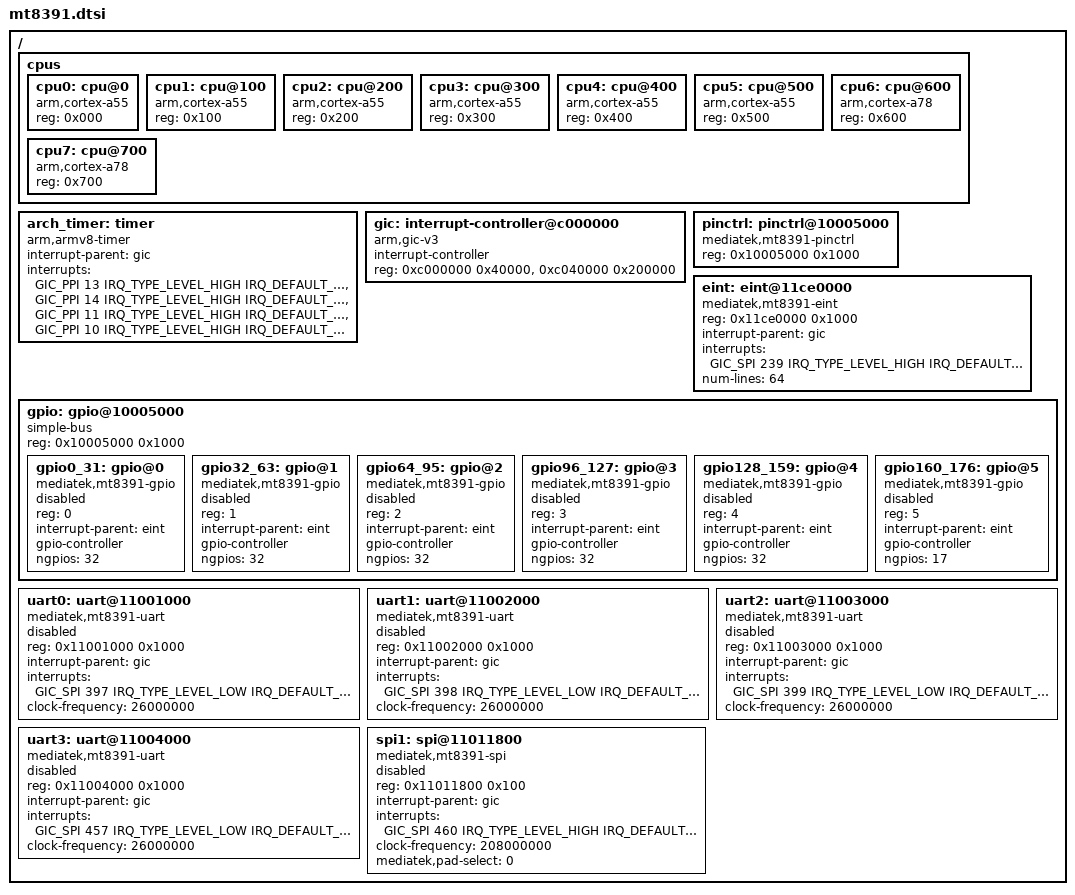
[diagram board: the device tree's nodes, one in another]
// SPDX-License-Identifier: GPL-2.0+
/*
 * Copyright (c) 2025 MediaTek Inc.
 *
 */

#include <arm64/armv8-a.dtsi>
#include <zephyr/dt-bindings/interrupt-controller/arm-gic.h>
#include <zephyr/dt-bindings/interrupt-controller/mtk-irq.h>


/ {
	#address-cells = <1>;
	#size-cells = <1>;

	cpus {
		#address-cells = <1>;
		#size-cells = <0>;

		cpu0: cpu@0 {
			device_type = "cpu";
			compatible = "arm,cortex-a55";
			reg = <0x000>;
		};

		cpu1: cpu@100 {
			device_type = "cpu";
			compatible = "arm,cortex-a55";
			reg = <0x100>;
		};

		cpu2: cpu@200 {
			device_type = "cpu";
			compatible = "arm,cortex-a55";
			reg = <0x200>;
		};

		cpu3: cpu@300 {
			device_type = "cpu";
			compatible = "arm,cortex-a55";
			reg = <0x300>;
		};
		
		cpu4: cpu@400 {
			device_type = "cpu";
			compatible = "arm,cortex-a55";
			reg = <0x400>;
		};

		cpu5: cpu@500 {
			device_type = "cpu";
			compatible = "arm,cortex-a55";
			reg = <0x500>;
		};

		cpu6: cpu@600 {
			device_type = "cpu";
			compatible = "arm,cortex-a78";
			reg = <0x600>;
		};

		cpu7: cpu@700 {
			device_type = "cpu";
			compatible = "arm,cortex-a78";
			reg = <0x700>;
		};
	};

	arch_timer: timer {
		compatible = "arm,armv8-timer";
		interrupt-parent = <&gic>;
		interrupts = <GIC_PPI 13 IRQ_TYPE_LEVEL_HIGH IRQ_DEFAULT_PRIORITY>,
				 <GIC_PPI 14 IRQ_TYPE_LEVEL_HIGH IRQ_DEFAULT_PRIORITY>,
				 <GIC_PPI 11 IRQ_TYPE_LEVEL_HIGH IRQ_DEFAULT_PRIORITY>,
				 <GIC_PPI 10 IRQ_TYPE_LEVEL_HIGH IRQ_DEFAULT_PRIORITY>;
	};

	gic: interrupt-controller@c000000 {
		compatible = "arm,gic-v3", "arm,gic";
		#interrupt-cells = <4>;
		#address-cells = <0>;
		interrupt-controller;
		reg = <0xc000000 0x40000>,
			  <0xc040000 0x200000>;
		status = "okay";
	};

	pinctrl: pinctrl@10005000 {
		compatible = "mediatek,mt8391-pinctrl";
		reg = <0x10005000 0x1000>;
		#address-cells = <1>;
		#size-cells = <0>;
		status = "okay";
	};

	/* MT8391 (mt8189 silicon) splits EINT into five per-pad-cluster
	 * instances (Linux "apirq": e/s/w/c/n) sharing one GIC interrupt,
	 * with a per-pad (instance, index) mapping - pad number does NOT
	 * equal EINT line. This node describes instance 0 ("eint-e",
	 * e.g. pads 108-110 map to local indices 44-46). The GPIO driver
	 * currently emulates edge interrupts by polling DIN and does not
	 * touch EINT registers; a future dedicated-EINT port must add the
	 * pad translation and per-instance handling before use.
	 */
	eint: eint@11ce0000 {
		compatible = "mediatek,mt8391-eint";
		reg = <0x11ce0000 0x1000>;
		interrupt-parent = <&gic>;
		interrupts = <GIC_SPI 239 IRQ_TYPE_LEVEL_HIGH IRQ_DEFAULT_PRIORITY>;
		num-lines = <64>;	/* instance-local indices */
		#address-cells = <1>;
		#size-cells = <0>;
		status = "okay";
	};

	gpio: gpio@10005000 {
		compatible = "simple-bus";
		reg = <0x10005000 0x1000>;
		#address-cells = <1>;
		#size-cells = <0>;

		gpio0_31: gpio@0 {
			compatible = "mediatek,mt8391-gpio";
			reg = <0>;
			interrupt-parent = <&eint>;
			gpio-controller;
			#gpio-cells = <2>;
			ngpios = <32>;
			status = "disabled";
		};

		gpio32_63: gpio@1 {
			compatible = "mediatek,mt8391-gpio";
			reg = <1>;
			interrupt-parent = <&eint>;
			gpio-controller;
			#gpio-cells = <2>;
			ngpios = <32>;
			status = "disabled";
		};

		gpio64_95: gpio@2 {
			compatible = "mediatek,mt8391-gpio";
			reg = <2>;
			interrupt-parent = <&eint>;
			gpio-controller;
			#gpio-cells = <2>;
			ngpios = <32>;
			status = "disabled";
		};

		gpio96_127: gpio@3 {
			compatible = "mediatek,mt8391-gpio";
			reg = <3>;
			interrupt-parent = <&eint>;
			gpio-controller;
			#gpio-cells = <2>;
			ngpios = <32>;
			status = "disabled";
		};

		gpio128_159: gpio@4 {
			compatible = "mediatek,mt8391-gpio";
			reg = <4>;
			interrupt-parent = <&eint>;
			gpio-controller;
			#gpio-cells = <2>;
			ngpios = <32>;
			status = "disabled";
		};

		gpio160_176: gpio@5 {
			compatible = "mediatek,mt8391-gpio";
			reg = <5>;
			interrupt-parent = <&eint>;
			gpio-controller;
			#gpio-cells = <2>;
			ngpios = <17>;
			status = "disabled";
		};
	};

	/* UART0..3 addresses verified against the Linux mt8189.dtsi and the
	 * live board 2026-10-06.
	 */
	uart0: uart@11001000 {
		compatible = "mediatek,mt8391-uart";
		reg = <0x11001000 0x1000>;
		interrupt-parent = <&gic>;
		interrupts = <GIC_SPI 397 IRQ_TYPE_LEVEL_LOW IRQ_DEFAULT_PRIORITY>;
        clock-frequency = <26000000>;
		status = "disabled";
	};

	uart1: uart@11002000 {
		compatible = "mediatek,mt8391-uart";
		reg = <0x11002000 0x1000>;
		interrupt-parent = <&gic>;
		interrupts = <GIC_SPI 398 IRQ_TYPE_LEVEL_LOW IRQ_DEFAULT_PRIORITY>;
        clock-frequency = <26000000>;
		status = "disabled";
	};

	uart2: uart@11003000 {
		compatible = "mediatek,mt8391-uart";
		reg = <0x11003000 0x1000>;
		interrupt-parent = <&gic>;
		interrupts = <GIC_SPI 399 IRQ_TYPE_LEVEL_LOW IRQ_DEFAULT_PRIORITY>;
        clock-frequency = <26000000>;
		status = "disabled";
	};

	uart3: uart@11004000 {
		compatible = "mediatek,mt8391-uart";
		reg = <0x11004000 0x1000>;
		interrupt-parent = <&gic>;
		interrupts = <GIC_SPI 457 IRQ_TYPE_LEVEL_LOW IRQ_DEFAULT_PRIORITY>;
        clock-frequency = <26000000>;
		status = "disabled";
	};

	spi1: spi@11011800 {
		compatible = "mediatek,mt8391-spi";
		reg = <0x11011800 0x100>;
		interrupt-parent = <&gic>;
		interrupts = <GIC_SPI 460 IRQ_TYPE_LEVEL_HIGH IRQ_DEFAULT_PRIORITY>;
		clock-frequency = <208000000>;
		mediatek,pad-select = <0>;
		#address-cells = <1>;
		#size-cells = <0>;
		status = "disabled";
	};
/*
	i2s: i2s@10b10000 {
		compatible = "mediatek,mt8370-i2s";
		reg = <0x10b10000 0x1000>;
		interrupt-parent = <&gic>;
		interrupts = <GIC_SPI 822 IRQ_TYPE_LEVEL_LOW IRQ_DEFAULT_PRIORITY>;
		status = "disabled";
	};
*/
};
